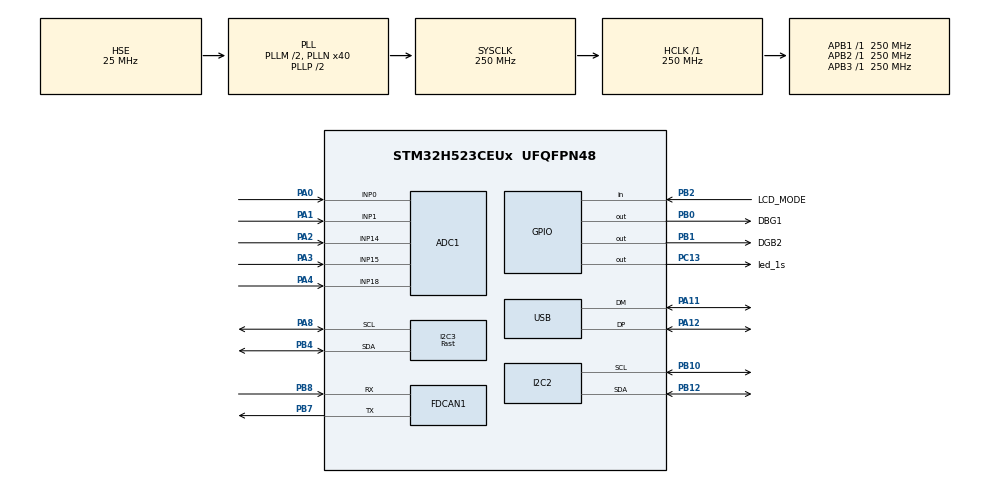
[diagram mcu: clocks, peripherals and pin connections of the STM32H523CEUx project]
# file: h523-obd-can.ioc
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ADC1.Channel-1\#ChannelRegularConversion=ADC_CHANNEL_0
ADC1.Channel-2\#ChannelRegularConversion=ADC_CHANNEL_1
ADC1.Channel-3\#ChannelRegularConversion=ADC_CHANNEL_14
ADC1.Channel-4\#ChannelRegularConversion=ADC_CHANNEL_15
ADC1.Channel-5\#ChannelRegularConversion=ADC_CHANNEL_18
ADC1.ClockPrescaler=ADC_CLOCK_ASYNC_DIV2
ADC1.ContinuousConvMode=DISABLE
ADC1.DMAContinuousRequests=ENABLE
ADC1.DataAlign=ADC_DATAALIGN_LEFT
ADC1.EOCSelection=ADC_EOC_SEQ_CONV
ADC1.ExternalTrigConv=ADC_EXTERNALTRIG_T6_TRGO
ADC1.MonitoredBy-1\#ChannelRegularConversion=__NULL
ADC1.MonitoredBy-2\#ChannelRegularConversion=__NULL
ADC1.MonitoredBy-3\#ChannelRegularConversion=__NULL
ADC1.MonitoredBy-4\#ChannelRegularConversion=__NULL
ADC1.MonitoredBy-5\#ChannelRegularConversion=__NULL
ADC1.NbrOfConversion=5
ADC1.NbrOfConversionFlag=1
ADC1.OffsetNumber-1\#ChannelRegularConversion=ADC_OFFSET_NONE
ADC1.OffsetNumber-2\#ChannelRegularConversion=ADC_OFFSET_NONE
ADC1.OffsetNumber-3\#ChannelRegularConversion=ADC_OFFSET_NONE
ADC1.OffsetNumber-4\#ChannelRegularConversion=ADC_OFFSET_NONE
ADC1.OffsetNumber-5\#ChannelRegularConversion=ADC_OFFSET_NONE
ADC1.Overrun=ADC_OVR_DATA_PRESERVED
ADC1.OversamplingMode=DISABLE
ADC1.Rank-1\#ChannelRegularConversion=1
ADC1.Rank-2\#ChannelRegularConversion=2
ADC1.Rank-3\#ChannelRegularConversion=3
ADC1.Rank-4\#ChannelRegularConversion=4
ADC1.Rank-5\#ChannelRegularConversion=5
ADC1.SamplingTime-1\#ChannelRegularConversion=ADC_SAMPLETIME_12CYCLES_5
ADC1.SamplingTime-2\#ChannelRegularConversion=ADC_SAMPLETIME_12CYCLES_5
ADC1.SamplingTime-3\#ChannelRegularConversion=ADC_SAMPLETIME_12CYCLES_5
ADC1.SamplingTime-4\#ChannelRegularConversion=ADC_SAMPLETIME_12CYCLES_5
ADC1.SamplingTime-5\#ChannelRegularConversion=ADC_SAMPLETIME_12CYCLES_5
ADC1.master=1
BOOTPATH.BootPathName=LEGACY
BOOTPATH.UserSelectedBootPath=LEGACY
CORTEX_M33_NS.userName=CORTEX_M33
FDCAN1.AutoRetransmission=ENABLE
FDCAN1.CalculateBaudRateNominal=500000
FDCAN1.CalculateTimeBitNominal=2000
FDCAN1.CalculateTimeQuantumNominal=16.0
FDCAN1.DataPrescaler=1
FDCAN1.NominalPrescaler=4
FDCAN1.NominalSyncJumpWidth=1
FDCAN1.NominalTimeSeg1=93
FDCAN1.NominalTimeSeg2=31
FDCAN1.StdFiltersNbr=1
GPDMA1.CIRCULARMODE_GPDMACH0=ENABLE
GPDMA1.DATAHANDLING_GPDMACH0=NONE
GPDMA1.DESTBURSTLENGTH_GPDMACH0=1
GPDMA1.DESTDATAWIDTH_GPDMACH0=DMA_DEST_DATAWIDTH_HALFWORD
GPDMA1.DESTINC_GPDMACH0=DMA_DINC_INCREMENTED
GPDMA1.IPHANDLE_GPDMACH0-SIMPLEREQUEST_GPDMACH0=__NULL
GPDMA1.REQUEST_GPDMACH0=GPDMA1_REQUEST_ADC1
GPDMA1.SRCBURSTLENGTH_GPDMACH0=1
GPDMA1.SRCDATAWIDTH_GPDMACH0=DMA_SRC_DATAWIDTH_HALFWORD
GPDMA1.TRIGGERPOLARITY_GPDMACH0=DMA_TRIG_POLARITY_MASKED
I2C2.Timing=0x60808CD3
I2C3.I2C_Speed_Mode=I2C_Fast
I2C3.Timing=0x10C043E5
Mcu.Family=STM32H5
Mcu.Name=STM32H523CEUx
Mcu.Package=UFQFPN48
NVIC.FDCAN1_IT0_IRQn=true\:9\:0\:true\:false\:true\:true\:true\:true
NVIC.GPDMA1_Channel0_IRQn=true\:0\:0\:false\:false\:true\:false\:true\:true
NVIC.I2C2_ER_IRQn=true\:0\:0\:false\:false\:true\:true\:true\:true
NVIC.I2C2_EV_IRQn=true\:0\:0\:false\:false\:true\:true\:true\:true
NVIC.I2C3_ER_IRQn=true\:0\:0\:false\:false\:true\:true\:true\:true
NVIC.I2C3_EV_IRQn=true\:0\:0\:false\:false\:true\:true\:true\:true
NVIC.PriorityGroup=NVIC_PRIORITYGROUP_4
NVIC.TIM6_IRQn=true\:0\:0\:false\:false\:true\:true\:true\:true
NVIC.TIM7_IRQn=true\:11\:0\:true\:false\:true\:true\:true\:true
NVIC.USB_DRD_FS_IRQn=true\:10\:0\:true\:false\:true\:true\:true\:true
PA0.Signal=ADCx_INP0
PA1.Signal=ADCx_INP1
PA11.Mode=Device
PA11.Signal=USB_DM
PA12.Mode=Device
PA12.Signal=USB_DP
PA13(JTMS/SWDIO).Mode=Serial_Wire
PA13(JTMS/SWDIO).Signal=DEBUG_JTMS-SWDIO
PA14(JTCK/SWCLK).Mode=Serial_Wire
PA14(JTCK/SWCLK).Signal=DEBUG_JTCK-SWCLK
PA2.Signal=ADCx_INP14
PA3.Signal=ADCx_INP15
PA4.Signal=ADCx_INP18
PA8.Mode=I2C
PA8.Signal=I2C3_SCL
PB0.GPIO_Label=DBG1
PB0.GPIO_Speed=GPIO_SPEED_FREQ_VERY_HIGH
PB0.PinState=GPIO_PIN_RESET
PB0.Signal=GPIO_Output
PB1.GPIO_Label=DGB2
PB1.GPIO_Speed=GPIO_SPEED_FREQ_VERY_HIGH
PB1.Signal=GPIO_Output
PB10.Mode=I2C
PB10.Signal=I2C2_SCL
PB12.Mode=I2C
PB12.Signal=I2C2_SDA
PB2.GPIO_Label=LCD_MODE
PB2.Signal=GPIO_Input
PB4(NJTRST).Mode=I2C
PB4(NJTRST).Signal=I2C3_SDA
PB7.Mode=FDCAN_Activate
PB7.Signal=FDCAN1_TX
PB8.Mode=FDCAN_Activate
PB8.Signal=FDCAN1_RX
PC13.GPIO_Label=led_1s
PC13.PinState=GPIO_PIN_RESET
PC13.Signal=GPIO_Output
PH0-OSC_IN(PH0).Mode=HSE-External-Oscillator
PH0-OSC_IN(PH0).Signal=RCC_OSC_IN
PH1-OSC_OUT(PH1).Mode=HSE-External-Oscillator
PH1-OSC_OUT(PH1).Signal=RCC_OSC_OUT
ProjectManager.HeapSize=0x200
ProjectManager.StackSize=0x400
ProjectManager.TargetToolchain=STM32CubeIDE
RCC.ADCCLockSelection=RCC_ADCDACCLKSOURCE_PLL2R
RCC.ADCFreq_Value=125000000
RCC.AHBFreq_Value=250000000
RCC.APB1Freq_Value=250000000
RCC.APB1TimFreq_Value=250000000
RCC.APB2Freq_Value=250000000
RCC.APB2TimFreq_Value=250000000
RCC.APB3Freq_Value=250000000
RCC.CSI_VALUE=4000000
RCC.CortexFreq_Value=250000000
RCC.EPOD_VALUE=25000000
RCC.FDCANClockSelection=RCC_FDCANCLKSOURCE_PLL1Q
RCC.HCLKFreq_Value=250000000
RCC.HSE_VALUE=25000000
RCC.HSI48_VALUE=48000000
RCC.HSI_VALUE=64000000
RCC.LSE_VALUE=32768
RCC.LSIRC_VALUE=32000
RCC.PLL2FRACN=0
RCC.PLL2M=2
RCC.PLL2N=40
RCC.PLL2R=4
RCC.PLL2Source=RCC_PLL2_SOURCE_HSE
RCC.PLL3FRACN=0
RCC.PLLFRACN=0
RCC.PLLM=2
RCC.PLLN=40
RCC.PLLSourceVirtual=RCC_PLL1_SOURCE_HSE
RCC.SYSCLKFreq_VALUE=250000000
RCC.SYSCLKSource=RCC_SYSCLKSOURCE_PLLCLK
RCC.USBFreq_Value=48000000
RCC.VCOOutputFreq_Value=500000000
SH.ADCx_INP0.0=ADC1_INP0,IN0-Single-Ended
SH.ADCx_INP1.0=ADC1_INP1,IN1-Single-Ended
SH.ADCx_INP14.0=ADC1_INP14,IN14-Single-Ended
SH.ADCx_INP15.0=ADC1_INP15,IN15-Single-Ended
SH.ADCx_INP18.0=ADC1_INP18,IN18-Single-Ended
TIM6.AutoReloadPreload=TIM_AUTORELOAD_PRELOAD_ENABLE
TIM6.PeriodNoDither=25000
TIM6.TIM_MasterOutputTrigger=TIM_TRGO_UPDATE
TIM7.AutoReloadPreload=TIM_AUTORELOAD_PRELOAD_ENABLE
TIM7.PeriodNoDither=99
TIM7.Prescaler=249
TIM7.TIM_MasterOutputTrigger=TIM_TRGO_UPDATE
USB.VirtualMode=Device_Only
VP_BOOTPATH_VS_BOOTPATH.Mode=BP_Activate
VP_CORTEX_M33_NS_VS_Hclk.Mode=Hclk_Mode
VP_GPDMA1_VS_GPDMACH0.Mode=SIMPLEREQUEST_GPDMACH0
VP_MEMORYMAP_VS_MEMORYMAP.Mode=CurAppReg
VP_PWR_VS_DBSignals.Mode=DisableDeadBatterySignals
VP_PWR_VS_LPOM.Mode=PowerOptimisation
VP_PWR_VS_SECSignals.Mode=Security/Privilege
VP_TIM6_VS_ClockSourceINT.Mode=Enable_Timer
VP_TIM7_VS_ClockSourceINT.Mode=Enable_Timer
board=custom

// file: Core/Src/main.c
/* USER CODE BEGIN Header */
/**
  ******************************************************************************
  * @file           : main.c
  * @brief          : Main program body
  ******************************************************************************
  * @attention
  *
  * Copyright (c) 2026 STMicroelectronics.
  * All rights reserved.
  *
  * This software is licensed under terms that can be found in the LICENSE file
  * in the root directory of this software component.
  * If no LICENSE file comes with this software, it is provided AS-IS.
  *
  ******************************************************************************
  */
/* USER CODE END Header */
#include "main.h"
#include "adc.h"
#include "fdcan.h"
#include "gpdma.h"
#include "i2c.h"
#include "tim.h"
#include "usb.h"
#include "gpio.h"

void SystemClock_Config(void);

int main(void)
{

  /* MCU Configuration--------------------------------------------------------*/

  /* Reset of all peripherals, Initializes the Flash interface and the Systick. */
  HAL_Init();

  /* Configure the system clock */
  SystemClock_Config();

  /* Initialize all configured peripherals */
  MX_GPIO_Init();
  MX_GPDMA1_Init();
  MX_TIM7_Init();
  MX_USB_PCD_Init();
  MX_ADC1_Init();
  MX_FDCAN1_Init();
  MX_TIM6_Init();
  MX_I2C2_Init();
  MX_I2C3_Init();
  /* USER CODE BEGIN 2 */
  custom_init();
//    HAL_GPIO_WritePin(GPIOC,GPIO_PIN_13,1);

  /* USER CODE END 2 */

  /* Infinite loop */
  while (1)
  {

    /* USER CODE BEGIN 3 */
	  mainloop();
  }
  /* USER CODE END 3 */
}

void SystemClock_Config(void)
{
  RCC_OscInitTypeDef RCC_OscInitStruct = {0};
  RCC_ClkInitTypeDef RCC_ClkInitStruct = {0};

  /** Configure the main internal regulator output voltage
  */
  __HAL_PWR_VOLTAGESCALING_CONFIG(PWR_REGULATOR_VOLTAGE_SCALE0);

  while(!__HAL_PWR_GET_FLAG(PWR_FLAG_VOSRDY)) {}

  /** Initializes the RCC Oscillators according to the specified parameters
  * in the RCC_OscInitTypeDef structure.
  */
  RCC_OscInitStruct.OscillatorType = RCC_OSCILLATORTYPE_HSI48|RCC_OSCILLATORTYPE_HSE;
  RCC_OscInitStruct.HSEState = RCC_HSE_ON;
  RCC_OscInitStruct.HSI48State = RCC_HSI48_ON;
  RCC_OscInitStruct.PLL.PLLState = RCC_PLL_ON;
  RCC_OscInitStruct.PLL.PLLSource = RCC_PLL1_SOURCE_HSE;
  RCC_OscInitStruct.PLL.PLLM = 2;
  RCC_OscInitStruct.PLL.PLLN = 40;
  RCC_OscInitStruct.PLL.PLLP = 2;
  RCC_OscInitStruct.PLL.PLLQ = 2;
  RCC_OscInitStruct.PLL.PLLR = 2;
  RCC_OscInitStruct.PLL.PLLRGE = RCC_PLL1_VCIRANGE_3;
  RCC_OscInitStruct.PLL.PLLVCOSEL = RCC_PLL1_VCORANGE_WIDE;
  RCC_OscInitStruct.PLL.PLLFRACN = 0;
  if (HAL_RCC_OscConfig(&RCC_OscInitStruct) != HAL_OK)
  {
    Error_Handler();
  }

  /** Initializes the CPU, AHB and APB buses clocks
  */
  RCC_ClkInitStruct.ClockType = RCC_CLOCKTYPE_HCLK|RCC_CLOCKTYPE_SYSCLK
                              |RCC_CLOCKTYPE_PCLK1|RCC_CLOCKTYPE_PCLK2
                              |RCC_CLOCKTYPE_PCLK3;
  RCC_ClkInitStruct.SYSCLKSource = RCC_SYSCLKSOURCE_PLLCLK;
  RCC_ClkInitStruct.AHBCLKDivider = RCC_SYSCLK_DIV1;
  RCC_ClkInitStruct.APB1CLKDivider = RCC_HCLK_DIV1;
  RCC_ClkInitStruct.APB2CLKDivider = RCC_HCLK_DIV1;
  RCC_ClkInitStruct.APB3CLKDivider = RCC_HCLK_DIV1;

  if (HAL_RCC_ClockConfig(&RCC_ClkInitStruct, FLASH_LATENCY_5) != HAL_OK)
  {
    Error_Handler();
  }

  /** Configure the programming delay
  */
  __HAL_FLASH_SET_PROGRAM_DELAY(FLASH_PROGRAMMING_DELAY_2);
}

void Error_Handler(void)
{
  __disable_irq();
  while (1)
  {
  }
}
